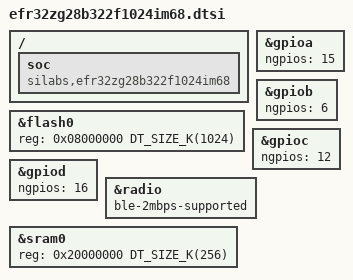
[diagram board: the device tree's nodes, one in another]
/*
 * Copyright (c) 2025 Shontal Biton
 * Copyright (c) 2025 Silicon Laboratories Inc.
 *
 * SPDX-License-Identifier: Apache-2.0
 */

#include <mem.h>
#include <silabs/xg28/efr32zg28.dtsi>

/ {
	soc {
		compatible = "silabs,efr32zg28b322f1024im68", "silabs,efr32zg28", "silabs,xg28",
			     "silabs,efr32", "simple-bus";
	};
};

&flash0 {
	reg = <0x08000000 DT_SIZE_K(1024)>;
};

&gpioa {
	ngpios = <15>;
};

&gpiob {
	ngpios = <6>;
};

&gpioc {
	ngpios = <12>;
};

&gpiod {
	ngpios = <16>;
};

&radio {
	ble-2mbps-supported;
};

&sram0 {
	reg = <0x20000000 DT_SIZE_K(256)>;
};
